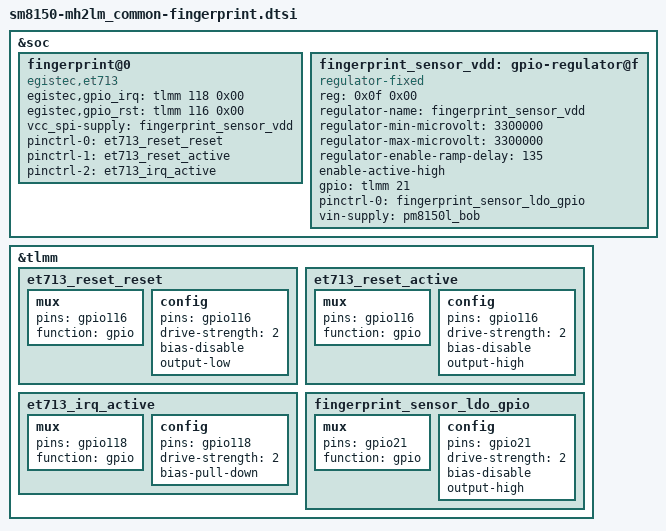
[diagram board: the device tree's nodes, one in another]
/*
 * Copyright (c) 2018, The Linux Foundation. All rights reserved.
 *
 * This program is free software; you can redistribute it and/or modify
 * it under the terms of the GNU General Public License version 2 and
 * only version 2 as published by the Free Software Foundation.
 *
 * This program is distributed in the hope that it will be useful,
 * but WITHOUT ANY WARRANTY; without even the implied warranty of
 * MERCHANTABILITY or FITNESS FOR A PARTICULAR PURPOSE. See the
 * GNU General Public License for more details.
 */

&soc {
	#address-cells = <1>;
	#size-cells = <1>;
	fingerprint@0 {
		compatible = "egistec,et713";

        
        egistec,gpio_irq = <&tlmm 118 0x00>;
        egistec,gpio_rst = <&tlmm 116 0x00>;
        vcc_spi-supply = <&fingerprint_sensor_vdd>;
		pinctrl-names = "et713_reset_reset",
						"et713_reset_active",
						"et713_irq_active";
		pinctrl-0 = <&et713_reset_reset>;
		pinctrl-1 = <&et713_reset_active>;
		pinctrl-2 = <&et713_irq_active>;

		status = "ok";
	};

	fingerprint_sensor_vdd: gpio-regulator@f {
		compatible = "regulator-fixed";
		reg = <0x0f 0x00>;
		regulator-name = "fingerprint_sensor_vdd";
		regulator-min-microvolt = <3300000>;
		regulator-max-microvolt = <3300000>;
		regulator-enable-ramp-delay = <135>; // TBD
		enable-active-high;
		gpio = <&tlmm 21 0>;
		pinctrl-names = "default";
		pinctrl-0 = <&fingerprint_sensor_ldo_gpio>;
		vin-supply = <&pm8150l_bob>;
	};
};

&tlmm {
	et713_reset_reset: et713_reset_reset {
		mux {
			pins = "gpio116";
			function = "gpio";
		};
		config {
			pins = "gpio116";
			drive-strength = <2>;
			bias-disable;
			output-low;
		};
	};

	et713_reset_active: et713_reset_active {
		mux {
			pins = "gpio116";
			function = "gpio";
		};
		config {
			pins = "gpio116";
			drive-strength = <2>;
			bias-disable;
			output-high;
		};
	};

	et713_irq_active: et713_irq_active {
		mux {
			pins = "gpio118";
			function = "gpio";
		};
		config {
			pins = "gpio118";
			drive-strength = <2>;
			bias-pull-down;
		};
	};

	fingerprint_sensor_ldo_gpio: fingerprint_sensor_ldo_gpio { // et713_ldo_high
		mux {
			pins = "gpio21";
			function = "gpio";
		};
		config {
			pins = "gpio21";
			drive-strength = <2>;
			bias-disable;
			output-high;
		};
	};
};

